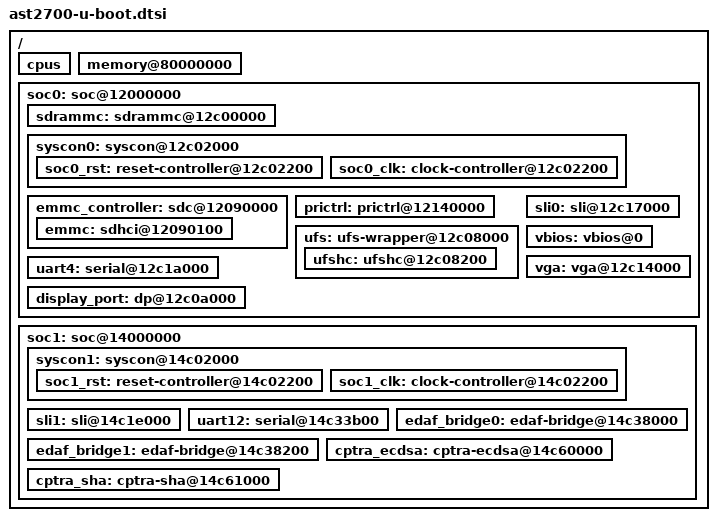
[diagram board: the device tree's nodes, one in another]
// SPDX-License-Identifier: (GPL-2.0 OR MIT)

/ {
	cpus {
		bootph-all;
	};

	memory@80000000 {
		bootph-all;
	};

	soc0: soc@12000000 {
		bootph-all;

		sdrammc: sdrammc@12c00000 {
			bootph-all;
		};

		syscon0: syscon@12c02000 {
			bootph-all;

			soc0_rst: reset-controller@12c02200 {
				bootph-all;
			};

			soc0_clk: clock-controller@12c02200 {
				bootph-all;
			};
		};

		emmc_controller: sdc@12090000 {
			bootph-all;

			emmc: sdhci@12090100 {
				bootph-all;
			};
		};

		prictrl: prictrl@12140000 {
			bootph-all;
		};

		ufs: ufs-wrapper@12c08000 {
			bootph-all;

			ufshc: ufshc@12c08200 {
				bootph-all;
			};
		};

		sli0: sli@12c17000 {
			bootph-all;
		};

		uart4: serial@12c1a000 {
			bootph-all;
		};

		vbios: vbios@0 {
			bootph-all;
		};

		display_port: dp@12c0a000 {
			bootph-all;
		};

		vga: vga@12c14000 {
			bootph-all;
		};
	};

	soc1: soc@14000000 {
		bootph-all;

		syscon1: syscon@14c02000 {
			bootph-all;

			soc1_rst: reset-controller@14c02200 {
				bootph-all;
			};

			soc1_clk: clock-controller@14c02200 {
				bootph-all;
			};
		};

		sli1: sli@14c1e000 {
			bootph-all;
		};

		uart12: serial@14c33b00 {
			bootph-all;
		};

		edaf_bridge0: edaf-bridge@14c38000 {
			bootph-all;
		};

		edaf_bridge1: edaf-bridge@14c38200 {
			bootph-all;
		};

		cptra_ecdsa: cptra-ecdsa@14c60000 {
			bootph-all;
		};

		cptra_sha: cptra-sha@14c61000 {
			bootph-all;
		};
	};

};
